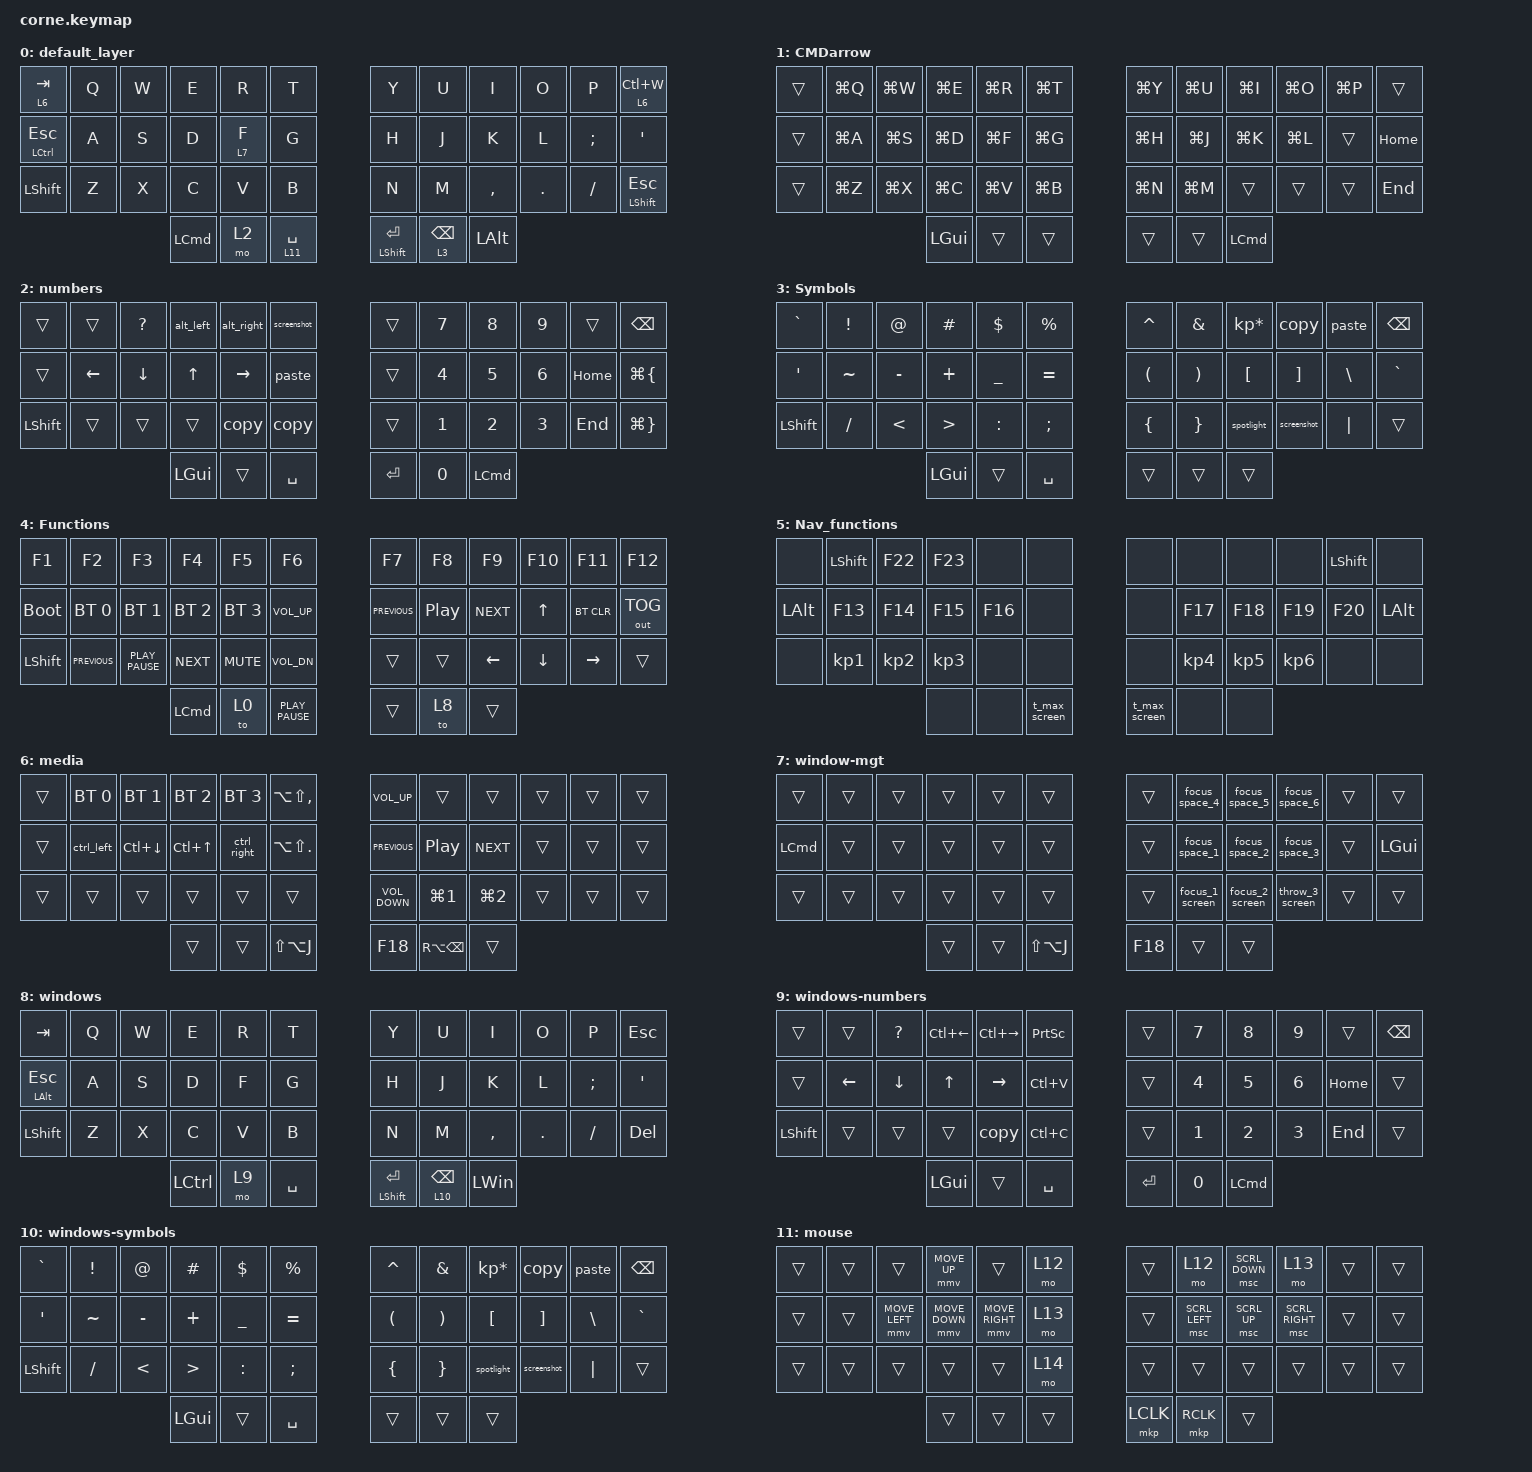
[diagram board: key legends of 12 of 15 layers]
/*
 * Copyright (c) 2020 The ZMK Contributors
 *
 * SPDX-License-Identifier: MIT
 */

#include <input/processors.dtsi>

#define ZMK_POINTING_DEFAULT_MOVE_VAL 1000  // default: 600
#define ZMK_POINTING_DEFAULT_SCRL_VAL 80    // default: 10

#include <behaviors.dtsi>
#include <dt-bindings/zmk/bt.h>
#include <dt-bindings/zmk/keys.h>
#include <dt-bindings/zmk/outputs.h>
#include <dt-bindings/zmk/pointing.h>

#define MOUSE 11
#define MOUSE_FAST 12
#define MOUSE_ULTRA_FAST 13

&mmv_input_listener {
    set_mouse_normal {
        layers = <MOUSE>;
        input-processors = <&zip_xy_scaler 2 1>;
    };
};

&mmv_input_listener {
    set_mouse_fast {
        layers = <MOUSE_FAST>;
        input-processors = <&zip_xy_scaler 3 1>;
    };
};

&mmv_input_listener {
    set_mouse_ultra_fast {
        layers = <MOUSE_ULTRA_FAST>;
        input-processors = <&zip_xy_scaler 4 1>;
    };
};

/ {
    combos {
        compatible = "zmk,combos";

        combo_control {
            bindings = <&mo 5>;
            key-positions = <41 35>;
            timeout-ms = <70>;
        };

        combo_space {
            bindings = <&kp ESC>;
            key-positions = <35 24>;
            timeout-ms = <40>;
        };

        combo_left_esc {
            bindings = <&mo 5>;
            key-positions = <24 36>;
            timeout-ms = <70>;
        };

        combo_vim {
            bindings = <&vim_exit>;
            key-positions = <37 40>;
            timeout-ms = <50>;
        };

        quick_tap_esc {
            bindings = <&kp ESC>;
            key-positions = <35 41>;
            timeout-ms = <20>;
        };

        quick_tap_esc_2 {
            bindings = <&kp ESC>;
            key-positions = <24 36>;
        };

        l4 {
            bindings = <&to 4>;
            key-positions = <36 41>;
        };

        chevron {
            bindings = <&kp LESS_THAN>;
            key-positions = <19 8>;
            require-prior-idle-ms = <100>;
        };

        chevron_right {
            bindings = <&kp GREATER_THAN>;
            key-positions = <8 21>;
            require-prior-idle-ms = <100>;
        };

        parenthesis_l {
            bindings = <&kp LEFT_PARENTHESIS>;
            key-positions = <19 20>;
        };

        parenthesis_right {
            bindings = <&kp RIGHT_PARENTHESIS>;
            key-positions = <20 21>;
        };

        brackets_left {
            bindings = <&kp LEFT_BRACKET>;
            key-positions = <31 32>;
        };

        bracket_right {
            bindings = <&kp RIGHT_BRACKET>;
            key-positions = <32 33>;
        };

        braces_left {
            bindings = <&kp LEFT_BRACE>;
            key-positions = <7 8>;
        };

        braces_right {
            bindings = <&kp RIGHT_BRACE>;
            key-positions = <8 9>;
        };

        slash {
            bindings = <&kp SLASH>;
            key-positions = <18 7>;
        };

        backslash {
            bindings = <&kp BACKSLASH>;
            key-positions = <6 19>;
        };

        pipe {
            bindings = <&kp PIPE>;
            key-positions = <6 18>;
        };

        period {
            bindings = <&kp PERIOD>;
            key-positions = <16 19>;
        };

        comma {
            bindings = <&kp COMMA>;
            key-positions = <17 18>;
        };

        single_quote {
            bindings = <&kp APOS>;
            key-positions = <5 6>;
        };

        double_quotes {
            bindings = <&kp DOUBLE_QUOTES>;
            key-positions = <4 7>;
        };

        grave {
            bindings = <&kp GRAVE>;
            key-positions = <5 4 6 7>;
        };

        plus {
            bindings = <&kp PLUS>;
            key-positions = <14 15 16>;
        };

        minus {
            bindings = <&kp MINUS>;
            key-positions = <15 16>;
        };

        switch_right {
            bindings = <&ctrl_right>;
            key-positions = <27 28>;
        };

        switch_left {
            bindings = <&ctrl_left>;
            key-positions = <26 27>;
        };

        switch {
            bindings = <&kp F18>;
            key-positions = <28 26>;
        };

        cmd_thumb {
            bindings = <&mt LEFT_GUI ESCAPE>;
            key-positions = <38 39>;
        };

        underscore {
            bindings = <&kp UNDER>;
            key-positions = <13 14 15 16>;
        };

        semi_colon {
            bindings = <&kp SEMICOLON>;
            key-positions = <29 30>;
        };

        ctrl-c {
            bindings = <&kp LC(C)>;
            key-positions = <23 12>;
        };

        jk_period {
            bindings = <&kp PERIOD>;
            key-positions = <30 31>;
        };

        kl_colon {
            bindings = <&kp COLON>;
            key-positions = <18 19>;
        };

        colon {
            bindings = <&kp COLON>;
            key-positions = <31 28>;
        };

        switch_personal {
            bindings = <&bt BT_SEL 0>;
            key-positions = <25 27>;
        };

        switch_work {
            bindings = <&bt BT_SEL 1>;
            key-positions = <25 28>;
        };

        lock_pc {
            bindings = <&kp LG(LC(Q))>;
            key-positions = <0 11 39 38>;
        };

        to-lol {
            bindings = <&to 11>;
            key-positions = <1 2 3 4>;
            require-prior-idle-ms = <1000>;
            layers = <8>;
        };
    };

    macros {
        t_max_screen: toggle_max_screen {
            compatible = "zmk,behavior-macro";
            #binding-cells = <0>;
            bindings = <&kp LG(LS(SPACE))>;
            label = "TOGGLE_MAX_SCREEN";
        };

        vim_exit: vim_exit {
            compatible = "zmk,behavior-macro";
            #binding-cells = <0>;
            bindings = <&kp LA(C) &kp COLON>;
            label = "VIM_EXIT";
        };

        screenshot: screenshot {
            compatible = "zmk,behavior-macro";
            #binding-cells = <0>;
            bindings = <&kp LG(LS(NUMBER_4))>;
            label = "SCREENSHOT";
        };

        spotlight: spotlight {
            compatible = "zmk,behavior-macro";
            #binding-cells = <0>;
            bindings = <&kp LG(SPACE)>;
            label = "SPOTLIGHT";
        };

        alt_left: alt_left {
            compatible = "zmk,behavior-macro";
            #binding-cells = <0>;
            bindings = <&kp LA(LEFT)>;
            label = "ALT_LEFT";
        };

        alt_right: alt_right {
            compatible = "zmk,behavior-macro";
            #binding-cells = <0>;
            bindings = <&kp LA(RIGHT)>;
            label = "ALT_RIGHT";
        };

        copy: copy {
            compatible = "zmk,behavior-macro";
            #binding-cells = <0>;
            bindings = <&kp LG(C)>;
            label = "COPY";
        };

        paste: paste {
            compatible = "zmk,behavior-macro";
            #binding-cells = <0>;
            bindings = <&kp LG(V)>;
            label = "PASTE";
        };

        ctrl_right: ctrl_right {
            compatible = "zmk,behavior-macro";
            #binding-cells = <0>;
            bindings = <&kp LC(RIGHT)>;
            label = "CTRL_RIGHT";
        };

        ctrl_left: ctrl_left {
            compatible = "zmk,behavior-macro";
            #binding-cells = <0>;
            bindings = <&kp LC(LEFT)>;
            label = "CTRL_LEFT";
        };

        focus_1_screen: focus_1_screen {
            compatible = "zmk,behavior-macro";
            #binding-cells = <0>;
            bindings = <&kp LS(LA(LC(W)))>;
            label = "FOCUS_1_SCREEN";
        };

        focus_2_screen: focus_2_screen {
            compatible = "zmk,behavior-macro";
            #binding-cells = <0>;
            bindings = <&kp LS(LA(LC(E)))>;
            label = "FOCUS_2_SCREEN";
        };

        focus_3_screen: focus_3_screen {
            compatible = "zmk,behavior-macro";
            #binding-cells = <0>;
            bindings = <&kp LS(LA(LC(R)))>;
            label = "FOCUS_3_SCREEN";
        };

        throw_1_screen: throw_1_screen {
            compatible = "zmk,behavior-macro";
            #binding-cells = <0>;
            bindings = <&kp LS(LA(LC(M)))>;
            label = "THROW_1_SCREEN";
        };

        throw_2_screen: throw_2_screen {
            compatible = "zmk,behavior-macro";
            #binding-cells = <0>;
            bindings = <&kp LS(LA(LC(E)))>;
            label = "THROW_2_SCREEN";
        };

        throw_3_screen: throw_3_screen {
            compatible = "zmk,behavior-macro";
            #binding-cells = <0>;
            bindings = <&kp LS(LA(LC(R)))>;
            label = "THROW_3_SCREEN";
        };

        throw_1_space: throw_1_space {
            compatible = "zmk,behavior-macro";
            #binding-cells = <0>;
            bindings = <&kp LS(LA(LC(LG(J))))>;
            label = "THROW_1_SPACE";
        };

        throw_2_space: throw_2_space {
            compatible = "zmk,behavior-macro";
            #binding-cells = <0>;
            bindings = <&kp LS(LA(LC(LG(K))))>;
            label = "THROW_2_SPACE";
        };

        throw_3_space: throw_3_space {
            compatible = "zmk,behavior-macro";
            #binding-cells = <0>;
            bindings = <&kp LS(LA(LC(LG(L))))>;
            label = "THROW_3_SPACE";
        };

        throw_4_space: throw_4_space {
            compatible = "zmk,behavior-macro";
            #binding-cells = <0>;
            bindings = <&kp LS(LA(LC(LG(U))))>;
            label = "THROW_4_SPACE";
        };

        throw_5_space: throw_5_space {
            compatible = "zmk,behavior-macro";
            #binding-cells = <0>;
            bindings = <&kp LS(LA(LC(LG(I))))>;
            label = "THROW_5_SPACE";
        };

        throw_6_space: throw_6_space {
            compatible = "zmk,behavior-macro";
            #binding-cells = <0>;
            bindings = <&kp LS(LC(LA(LG(O))))>;
            label = "THROW_6_SPACE";
        };

        focus_space_1: focus_space_1 {
            compatible = "zmk,behavior-macro";
            #binding-cells = <0>;
            bindings = <&kp LS(LA(LC(J)))>;
            label = "FOCUS_SPACE_1";
        };

        focus_space_2: focus_space_2 {
            compatible = "zmk,behavior-macro";
            #binding-cells = <0>;
            bindings = <&kp LS(LC(LA(K)))>;
            label = "FOCUS_SPACE_2";
        };

        focus_space_3: focus_space_3 {
            compatible = "zmk,behavior-macro";
            #binding-cells = <0>;
            bindings = <&kp LS(LA(LC(L)))>;
            label = "FOCUS_SPACE_3";
        };

        focus_space_4: focus_space_4 {
            compatible = "zmk,behavior-macro";
            #binding-cells = <0>;
            bindings = <&kp LS(LA(LC(U)))>;
            label = "FOCUS_SPACE_4";
        };

        focus_space_5: focus_space_5 {
            compatible = "zmk,behavior-macro";
            #binding-cells = <0>;
            bindings = <&kp LS(LA(LC(I)))>;
            label = "FOCUS_SPACE_5";
        };

        focus_space_6: focus_space_6 {
            compatible = "zmk,behavior-macro";
            #binding-cells = <0>;
            bindings = <&kp LS(LA(LC(O)))>;
            label = "FOCUS_SPACE_6";
        };

        attach_windows: attatch_windows {
            compatible = "zmk,behavior-macro";
            #binding-cells = <0>;
            bindings = <&bt BT_SEL 3 &to 8>;
            label = "ATTATCH_WINDOWS";
        };

        attach_mac_personal: attach_mac_personal {
            compatible = "zmk,behavior-macro";
            #binding-cells = <0>;
            bindings = <&bt BT_SEL 0 &to 0>;
            label = "ATTACH_MAC_PERSONAL";
        };

        attach_mac_work: attach_mac_work {
            compatible = "zmk,behavior-macro";
            #binding-cells = <0>;
            bindings = <&bt BT_SEL 1 &to 0>;
            label = "ATTACH_MAC_WORK";
        };
    };

    keymap {
        compatible = "zmk,keymap";

        default_layer {
            // -----------------------------------------------------------------------------------------
            // |  TAB |  Q  |  W  |  E  |  R  |  T  |   |  Y  |  U   |  I  |  O  |  P  | BKSP |
            // | CTRL |  A  |  S  |  D  |  F  |  G  |   |  H  |  J   |  K  |  L  |  ;  |  '   |
            // | SHFT |  Z  |  X  |  C  |  V  |  B  |   |  N  |  M   |  ,  |  .  |  /  | ESC  |
            //                    | GUI | LWR | SPC |   | ENT | RSE  | ALT |

            bindings = <
&lt 6 TAB         &kp Q  &kp W  &kp E     &kp R    &kp T           &kp Y                 &kp U            &kp I      &kp O       &kp P      &lt 6 LC(W)
&mt LCTRL ESCAPE  &kp A  &kp S  &kp D     &lt 7 F  &kp G           &kp H                 &kp J            &kp K      &kp L       &kp SEMI   &kp SQT
&kp LEFT_SHIFT    &kp Z  &kp X  &kp C     &kp V    &kp B           &kp N                 &kp M            &kp COMMA  &kp PERIOD  &kp SLASH  &mt LEFT_SHIFT ESCAPE
                                &kp LCMD  &mo 2    &lt 11 SPACE    &mt LEFT_SHIFT ENTER  &lt 3 BACKSPACE  &kp LALT
            >;
        };

        CMDarrow {
            bindings = <
&trans  &kp LG(Q)  &kp LG(W)  &kp LG(E)  &kp LG(R)  &kp LG(T)    &kp LG(Y)  &kp LG(U)  &kp LG(I)         &kp LG(O)  &kp LG(P)  &trans
&trans  &kp LG(A)  &kp LG(S)  &kp LG(D)  &kp LG(F)  &kp LG(G)    &kp LG(H)  &kp LG(J)  &kp LG(K)         &kp LG(L)  &trans     &kp HOME
&trans  &kp LG(Z)  &kp LG(X)  &kp LG(C)  &kp LG(V)  &kp LG(B)    &kp LG(N)  &kp LG(M)  &trans            &trans     &trans     &kp END
                              &kp LGUI   &trans     &trans       &trans     &trans     &kp LEFT_COMMAND
            >;
        };

        numbers {
            // -----------------------------------------------------------------------------------------
            // |  TAB |  1  |  2  |  3  |  4  |  5  |   |  6  |  7  |  8  |  9  |  0  | BKSP |
            // | BTCLR| BT1 | BT2 | BT3 | BT4 | BT5 |   | LFT | DWN |  UP | RGT |     |      |
            // | SHFT |     |     |     |     |     |   |     |     |     |     |     |      |
            //                    | GUI |     | SPC |   | ENT |     | ALT |

            bindings = <
&trans     &trans    &kp QUESTION  &alt_left     &alt_right  &screenshot    &trans   &kp N7  &kp N8    &kp N9  &trans    &kp BSPC
&trans     &kp LEFT  &kp DOWN      &kp UP_ARROW  &kp RIGHT   &paste         &trans   &kp N4  &kp N5    &kp N6  &kp HOME  &kp LG(LEFT_BRACE)
&kp LSHFT  &trans    &trans        &trans        &copy       &copy          &trans   &kp N1  &kp N2    &kp N3  &kp END   &kp LG(RIGHT_BRACE)
                                   &kp LGUI      &trans      &kp SPACE      &kp RET  &kp N0  &kp LCMD
            >;
        };

        Symbols {
            // -----------------------------------------------------------------------------------------
            // |  TAB |  !  |  @  |  #  |  $  |  %  |   |  ^  |  &  |  *  |  (  |  )  | BKSP |
            // | CTRL |     |     |     |     |     |   |  -  |  =  |  [  |  ]  |  \  |  `   |
            // | SHFT |     |     |     |     |     |   |  _  |  +  |  {  |  }  | "|" |  ~   |
            //                    | GUI |     | SPC |   | ENT |     | ALT |

            bindings = <
&kp GRAVE  &kp EXCL   &kp AT         &kp HASH          &kp DLLR   &kp PRCNT        &kp CARET             &kp AMPS               &kp KP_MULTIPLY  &copy        &paste    &kp BSPC
&kp SQT    &kp TILDE  &kp MINUS      &kp PLUS          &kp UNDER  &kp EQUAL        &kp LEFT_PARENTHESIS  &kp RIGHT_PARENTHESIS  &kp LBKT         &kp RBKT     &kp BSLH  &kp GRAVE
&kp LSHFT  &kp SLASH  &kp LESS_THAN  &kp GREATER_THAN  &kp COLON  &kp SEMICOLON    &kp LEFT_BRACE        &kp RIGHT_BRACE        &spotlight       &screenshot  &kp PIPE  &trans
                                     &kp LGUI          &trans     &kp SPACE        &trans                &trans                 &trans
            >;
        };

        Functions {
            bindings = <
&kp F1       &kp F2          &kp F3            &kp F4            &kp F5        &kp F6              &kp F7          &kp F8            &kp F9          &kp F10       &kp F11          &kp F12
&bootloader  &bt BT_SEL 0    &bt BT_SEL 1      &bt BT_SEL 2      &bt BT_SEL 3  &kp C_VOLUME_UP     &kp C_PREVIOUS  &kp C_PLAY_PAUSE  &kp C_NEXT      &kp UP_ARROW  &bt BT_CLR       &out OUT_TOG
&kp LSHIFT   &kp K_PREVIOUS  &kp K_PLAY_PAUSE  &kp K_NEXT        &kp K_MUTE    &kp C_VOL_DN        &trans          &trans            &kp LEFT_ARROW  &kp DOWN      &kp RIGHT_ARROW  &trans
                                               &kp LEFT_COMMAND  &to 0         &kp K_PLAY_PAUSE    &trans          &to 8             &trans
            >;
        };

        Nav_functions {
            bindings = <
&none         &kp LEFT_SHIFT   &kp F22          &kp F23          &none    &none            &none          &none            &none            &none            &kp LSHIFT  &none
&kp LEFT_ALT  &kp F13          &kp F14          &kp F15          &kp F16  &none            &none          &kp F17          &kp F18          &kp F19          &kp F20     &kp LALT
&none         &kp KP_NUMBER_1  &kp KP_NUMBER_2  &kp KP_NUMBER_3  &none    &none            &none          &kp KP_NUMBER_4  &kp KP_NUMBER_5  &kp KP_NUMBER_6  &none       &none
                                                &none            &none    &t_max_screen    &t_max_screen  &none            &none
            >;
        };

        media {
            bindings = <
&trans  &bt BT_SEL 0  &bt BT_SEL 1  &bt BT_SEL 2      &bt BT_SEL 3  &kp LA(LS(COMMA))     &kp C_VOLUME_UP    &trans             &trans            &trans  &trans  &trans
&trans  &ctrl_left    &kp LC(DOWN)  &kp LC(UP_ARROW)  &ctrl_right   &kp LA(LS(PERIOD))    &kp C_PREVIOUS     &kp C_PP           &kp C_NEXT        &trans  &trans  &trans
&trans  &trans        &trans        &trans            &trans        &trans                &kp C_VOLUME_DOWN  &kp LG(NUMBER_1)   &kp LG(NUMBER_2)  &trans  &trans  &trans
                                    &trans            &trans        &kp LS(LA(J))         &kp F18            &kp RA(BACKSPACE)  &trans
            >;
        };

        window-mgt {
            bindings = <
&trans            &trans  &trans  &trans  &trans  &trans           &trans   &focus_space_4   &focus_space_5   &focus_space_6   &trans  &trans
&kp LEFT_COMMAND  &trans  &trans  &trans  &trans  &trans           &trans   &focus_space_1   &focus_space_2   &focus_space_3   &trans  &kp LEFT_GUI
&trans            &trans  &trans  &trans  &trans  &trans           &trans   &focus_1_screen  &focus_2_screen  &throw_3_screen  &trans  &trans
                                  &trans  &trans  &kp LS(LA(J))    &kp F18  &trans           &trans
            >;
        };

        windows {
            bindings = <
&kp TAB           &kp Q  &kp W  &kp E             &kp R  &kp T        &kp Y                 &kp U             &kp I         &kp O    &kp P     &kp ESC
&mt LEFT_ALT ESC  &kp A  &kp S  &kp D             &kp F  &kp G        &kp H                 &kp J             &kp K         &kp L    &kp SEMI  &kp SINGLE_QUOTE
&kp LSHFT         &kp Z  &kp X  &kp C             &kp V  &kp B        &kp N                 &kp M             &kp COMMA     &kp DOT  &kp FSLH  &kp DEL
                                &kp LEFT_CONTROL  &mo 9  &kp SPACE    &mt LEFT_SHIFT ENTER  &lt 10 BACKSPACE  &kp LEFT_WIN
            >;
        };

        windows-numbers {
            bindings = <
&trans     &trans    &kp QUESTION  &kp LC(LEFT)  &kp LC(RIGHT)  &kp PRINTSCREEN    &trans   &kp N7  &kp N8    &kp N9  &trans    &kp BSPC
&trans     &kp LEFT  &kp DOWN      &kp UP_ARROW  &kp RIGHT      &kp LC(V)          &trans   &kp N4  &kp N5    &kp N6  &kp HOME  &trans
&kp LSHFT  &trans    &trans        &trans        &copy          &kp LC(C)          &trans   &kp N1  &kp N2    &kp N3  &kp END   &trans
                                   &kp LGUI      &trans         &kp SPACE          &kp RET  &kp N0  &kp LCMD
            >;
        };

        windows-symbols {
            bindings = <
&kp GRAVE  &kp EXCL   &kp AT         &kp HASH          &kp DLLR   &kp PRCNT        &kp CARET             &kp AMPS               &kp KP_MULTIPLY  &copy        &paste    &kp BSPC
&kp SQT    &kp TILDE  &kp MINUS      &kp PLUS          &kp UNDER  &kp EQUAL        &kp LEFT_PARENTHESIS  &kp RIGHT_PARENTHESIS  &kp LBKT         &kp RBKT     &kp BSLH  &kp GRAVE
&kp LSHFT  &kp SLASH  &kp LESS_THAN  &kp GREATER_THAN  &kp COLON  &kp SEMICOLON    &kp LEFT_BRACE        &kp RIGHT_BRACE        &spotlight       &screenshot  &kp PIPE  &trans
                                     &kp LGUI          &trans     &kp SPACE        &trans                &trans                 &trans
            >;
        };

        mouse {
            bindings = <
&trans  &trans  &trans          &mmv MOVE_UP    &trans           &mo 12    &trans     &mo 12          &msc SCRL_DOWN  &mo 13           &trans  &trans
&trans  &trans  &mmv MOVE_LEFT  &mmv MOVE_DOWN  &mmv MOVE_RIGHT  &mo 13    &trans     &msc SCRL_LEFT  &msc SCRL_UP    &msc SCRL_RIGHT  &trans  &trans
&trans  &trans  &trans          &trans          &trans           &mo 14    &trans     &trans          &trans          &trans           &trans  &trans
                                &trans          &trans           &trans    &mkp LCLK  &mkp RCLK       &trans
            >;
        };

        mouse-fast {
            bindings = <
&trans  &trans  &trans          &mmv MOVE_UP    &trans           &mo 12    &trans     &mo 12          &msc SCRL_DOWN  &mo 13           &trans  &trans
&trans  &trans  &mmv MOVE_LEFT  &mmv MOVE_DOWN  &mmv MOVE_RIGHT  &mo 13    &trans     &msc SCRL_LEFT  &msc SCRL_UP    &msc SCRL_RIGHT  &trans  &trans
&trans  &trans  &trans          &trans          &trans           &mo 14    &trans     &trans          &trans          &trans           &trans  &trans
                                &trans          &trans           &trans    &mkp LCLK  &mkp RCLK       &trans
            >;
        };

        mouse-slow {
            bindings = <
&trans  &trans  &trans          &mmv MOVE_UP    &trans           &mo 12    &trans     &mo 12          &msc SCRL_UP    &mo 13           &trans  &trans
&trans  &trans  &mmv MOVE_LEFT  &mmv MOVE_DOWN  &mmv MOVE_RIGHT  &mo 13    &trans     &msc SCRL_LEFT  &msc SCRL_DOWN  &msc SCRL_RIGHT  &trans  &trans
&trans  &trans  &trans          &trans          &trans           &mo 14    &trans     &trans          &trans          &trans           &trans  &trans
                                &trans          &trans           &trans    &mkp LCLK  &mkp RCLK       &trans
            >;
        };

        mouse-xslow {
            bindings = <
&trans  &trans  &trans          &mmv MOVE_UP    &trans           &mo 12    &trans     &mo 12          &msc SCRL_UP    &mo 13           &trans  &trans
&trans  &trans  &mmv MOVE_LEFT  &mmv MOVE_DOWN  &mmv MOVE_RIGHT  &mo 13    &trans     &msc SCRL_LEFT  &msc SCRL_DOWN  &msc SCRL_RIGHT  &trans  &trans
&trans  &trans  &trans          &trans          &trans           &mo 14    &trans     &trans          &trans          &trans           &trans  &trans
                                &trans          &trans           &trans    &mkp LCLK  &mkp RCLK       &trans
            >;
        };
    };
};
